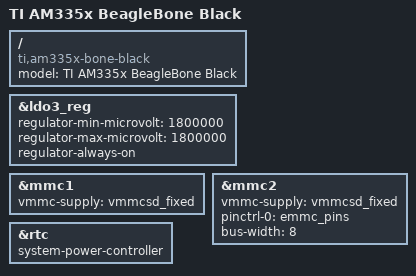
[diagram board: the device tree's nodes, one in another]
/dts-v1/;
/plugin/;

#include "am33xx.dtsi"
#include "am335x-bone-common.dtsi"
#include "am335x-boneblack-common.dtsi"
//#include "hcsr04.dtsi"
// JSD: not found in kernel repo!
// -> tried several pru and uio dts
// from https://github.com/RobertCNelson/bb.org-overlays
//#include "am335x-pru-uio.dtsi"

// JSD: potentially copy pru dtsi source from meta-ti
//#include "am335x-boneblack-prucape.dtsi"

/ {
	model = "TI AM335x BeagleBone Black";
	compatible = "ti,am335x-bone-black", "ti,am33xx";
};

&ldo3_reg {
	regulator-min-microvolt = <1800000>;
	regulator-max-microvolt = <1800000>;
	regulator-always-on;
};

&mmc1 {
	vmmc-supply = <&vmmcsd_fixed>;
};

&mmc2 {
	vmmc-supply = <&vmmcsd_fixed>;
	pinctrl-names = "default";
	pinctrl-0 = <&emmc_pins>;
	bus-width = <8>;
	status = "okay";
};

&rtc {
	system-power-controller;
};
